# cslr_mcbsp_001 register map
Vendor: Texas Instruments
Peripheral module from a debugger description file.
Registers are 32-bit, access not given, reset 0x0 unless marked. A register's access mark holds for its fields unless they carry their own. Offsets are as the file gives them; lines under a group give offsets from that group; [hi:lo] are bit positions; {n}, {i} and the like mark numbered series; 'fields as' and 'values as' point back to an identical list; <NAME> marks a mode.

## MCBSP — McBSP512
0x00 DRR ro — Data Receive Register
  [31:0] DRR — Receive data
0x04 DXR rw — Data Transmit Register
  [31:0] DXR — Transmit data
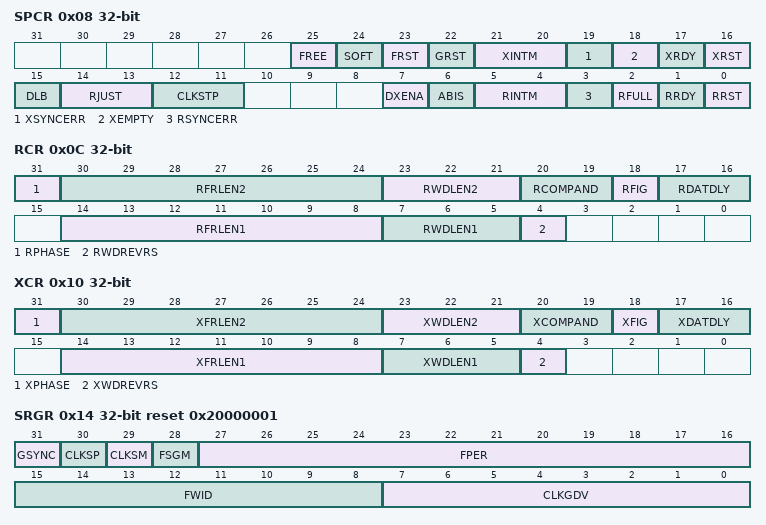
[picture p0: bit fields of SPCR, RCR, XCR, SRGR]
0x08 SPCR — Serial Port Control Register
  [25] FREE rw — McBSP emulation mode bit (free mode)
  [24] SOFT rw — McBSP emulation mode bit (soft mode)
  [23] FRST rw — Frame-sync logic reset bit (negative polarity)
  [22] GRST rw — Sample rate generator reset bit (negative polarity)
  [21:20] XINTM rw — Transmit interrupt mode bits
  [19] XSYNCERR rw — Transmit frame-sync error bit (Caution: if XINTM = 11b, writing a 1 to XSYNCERR triggers a transmit interrupt just as if a transmit frame-sync error occurred)
    0=CLEAR (Clear the transmit Frame Sync Error)
  [18] XEMPTY ro — Transmitter empty bit (negative polarity)
  [17] XRDY ro — Transmitter ready bit
  [16] XRST rw — Transmitter reset bit (negative polarity)
  [15] DLB rw — Digital loopback mode bit
  [14:13] RJUST rw — Receive sign-extension and justification mode bits
  [12:11] CLKSTP rw — Clock stop mode bits
  [7] DXENA rw — DX delay enabler mode bit
  [6] ABIS rw — A-bis mode bit
  [5:4] RINTM rw — Receive interrupt mode bits
  [3] RSYNCERR rw — Receive frame-sync error bit (Caution: If RINTM = 11b, writing a 1 to RSYNCERR triggers a receive interrupt just as if a receive frame-sync error occurred)
    0=CLEAR (Clear the receive Frame Sync Error)
  [2] RFULL ro — Receiver full bit
  [1] RRDY ro — Receiver ready bit
  [0] RRST rw — Receiver reset bit (negative polarity)
0x0C RCR — Receive Control Register
  [31] RPHASE rw — Receive phase number bit
  [30:24] RFRLEN2 rw — Receive frame length 2
  [23:21] RWDLEN2 rw — Receive word length 2
    0=8BITS; 1=12BITS; 2=16BITS; 3=20BITS; 4=24BITS; 5=32BITS
  [20:19] RCOMPAND rw — Receive companding mode bits
  [18] RFIG rw — Receive frame-sync ignore bit
  [17:16] RDATDLY rw — Receive data delay bits
  [14:8] RFRLEN1 rw — Receive frame length 1
  [7:5] RWDLEN1 rw — Receive word length 1
    0=8BITS; 1=12BITS; 2=16BITS; 3=20BITS; 4=24BITS; 5=32BITS
  [4] RWDREVRS rw — Receive 32-bit reversal feature 0: 32-bit reversal disabled 1: 32-bit reversal enabled. 32-bit data is received LSB first. RWDLEN should be set for 32-bit operation; else operation is undefined
0x10 XCR — Transmit Control Register
  [31] XPHASE rw — Transmit phase number bit
  [30:24] XFRLEN2 rw — Transmit frame length 2
  [23:21] XWDLEN2 rw — Transmit word length 2
    0=8BITS; 1=12BITS; 2=16BITS; 3=20BITS; 4=24BITS; 5=32BITS
  [20:19] XCOMPAND rw — Transmit companding mode bits
  [18] XFIG rw — Transmit frame-sync ignore bit
  [17:16] XDATDLY rw — Transmit data delay bits
  [14:8] XFRLEN1 rw — Transmit frame length 1
  [7:5] XWDLEN1 rw — Transmit word length 1
    0=8BITS; 1=12BITS; 2=16BITS; 3=20BITS; 4=24BITS; 5=32BITS
  [4] XWDREVRS rw — Transmit 32-bit reversal feature 0: 32-bit reversal disabled 1: 32-bit reversal enabled. 32-bit data is transmitted LSB first. RWDLEN should be set for 32-bit operation; else operation is undefined
0x14 SRGR rw reset 0x20000001 — Sample Rate Generator Register
  [31] GSYNC — Clock synchronization mode bit for CLKG
  [30] CLKSP — CLKS pin polarity bit
  [29] CLKSM — Sample rate generator input clock mode bit
  [28] FSGM — Sample rate generator transmit frame-sync mode bit
  [27:16] FPER — Frame-sync period bits for FSG
  [15:8] FWID — Frame-sync pulse width bits for FSG
  [7:0] CLKGDV — Divide-down value for CLKG
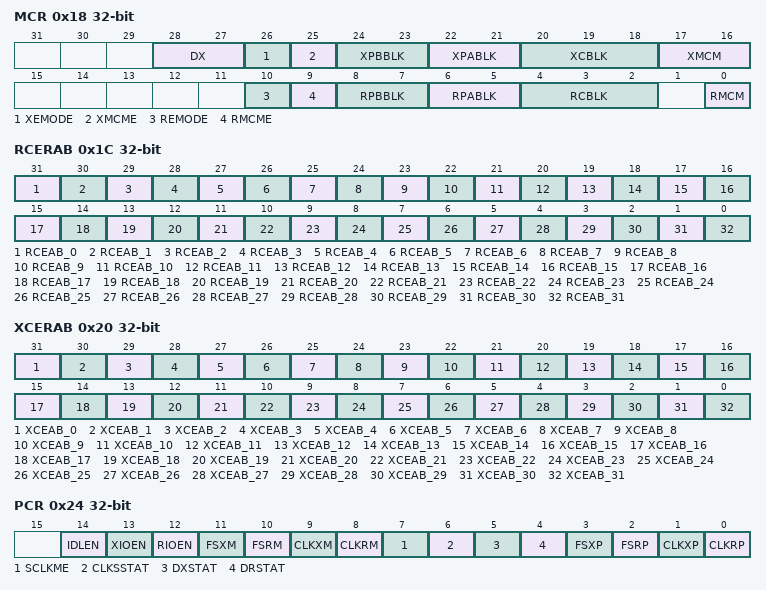
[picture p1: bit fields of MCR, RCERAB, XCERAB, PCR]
0x18 MCR — Multichannel Control Register
  [28:27] DX rw — Transmit pin mode configuration This is used to configure the DX pin state while the time slot is disabled 00b: Hi-Z 01b: Driven as 1 10b: Driven as 0 11b: Reserved
  [26] XEMODE rw — Multi-channel mode selection This bit is work with XMCM and XMCME bit to select the operation mode of the McBSP512 XEMODE XMCM XMCME Operation mode 0 00 0 Traditional operation mode 0 01/10/11 0 32 channel normal operation mode 0 xx 1 128 channel normal operation mode 1 00 0 512 channel mode with PDMA
  [25] XMCME rw — Transmit multichannel partition mode bit
    0=PARTITIONS2 (2-Partition Multi Channel Mode)
  [24:23] XPBBLK rw — Transmit partition B block bits
  [22:21] XPABLK rw — Transmit partition A block bits
  [20:18] XCBLK ro — Transmit current block indicator
  [17:16] XMCM rw — Transmit multichannel selection mode bits
    0=ENABLE (All Transmitter Channels are enabled); 1=DISABLE (All Transmitter Channels are disabled); 2=ENABLE_MASK (All Transmitter Channels are enabled and masked); 3=SYMMETRIC (Symmetric transmission and reception)
  [10] REMODE rw — Multi-channel mode selection This bit is work with RMCM and RMCME bit to select the operation mode of the McBSP512 REMODE RMCM RMCME Operation mode 0 00 0 Traditional operation mode 0 01/10/11 0 32 channel normal operation mode 0 xx 1 128 channel normal operation mode 1 00 0 512 channel mode with PDMA
  [9] RMCME rw — Receive multichannel partition mode bit
    0=PARTITIONS2 (2-Partition Multi Channel Mode); 1=PARTITIONS8 (8-Partition Multi Channel Mode)
  [8:7] RPBBLK rw — Receive partition B block bits
  [6:5] RPABLK rw — Receive partition A block bits
  [4:2] RCBLK ro — Receive current block indicator
  [0] RMCM rw — Receive multichannel selection mode bit
    0=ENABLE (All Receiver Channels are enabled); 1=DISABLE (All Receiver Channels are disabled)
0x1C RCERAB rw — Receive Channel Enable Register for Partition A and B
  [31-n] RCEAB_{n} (n=0..31) — Receive channel enable bits for partition A and B
0x20 XCERAB rw — Transmit Channel Enable Register for Partition A and B
  [31-n] XCEAB_{n} (n=0..31) — Transmit channel enable bits for partition A and B
0x24 PCR — Pin Control Register
  [14] IDLEN rw — Idle enable bit for the McBSP
  [13] XIOEN rw — Transmit I/O enable bit
  [12] RIOEN rw — Receive I/O enable bit
  [11] FSXM rw — Transmit frame-sync mode bit
    0=INPUT (Select FSX as Input Pin); 1=OUTPUT (Select FSX as Output Pin)
  [10] FSRM rw — Receive frame-sync mode bit
    0=INPUT (Select FSR as Input Pin); 1=OUTPUT (Select FSR as Output Pin)
  [9] CLKXM rw — Transmit clock mode bit
    0=INPUT (Select CLKX as Input Pin); 1=OUTPUT (Select CLKX as Output Pin)
  [8] CLKRM rw — Receive clock mode bit
    0=INPUT (Select CLKR as Input Pin); 1=OUTPUT (Select CLKR as Output Pin)
  [7] SCLKME rw — Sample rate generator input clock mode bit
  [6] CLKSSTAT ro — CLKS pin status bit
  [5] DXSTAT rw — DX pin status bit
  [4] DRSTAT ro — DR pin status bit
  [3] FSXP rw — Transmit frame-sync polarity bit
  [2] FSRP rw — Receive frame-sync polarity bit
  [1] CLKXP rw — Transmit clock polarity bit
  [0] CLKRP rw — Receive clock polarity bit
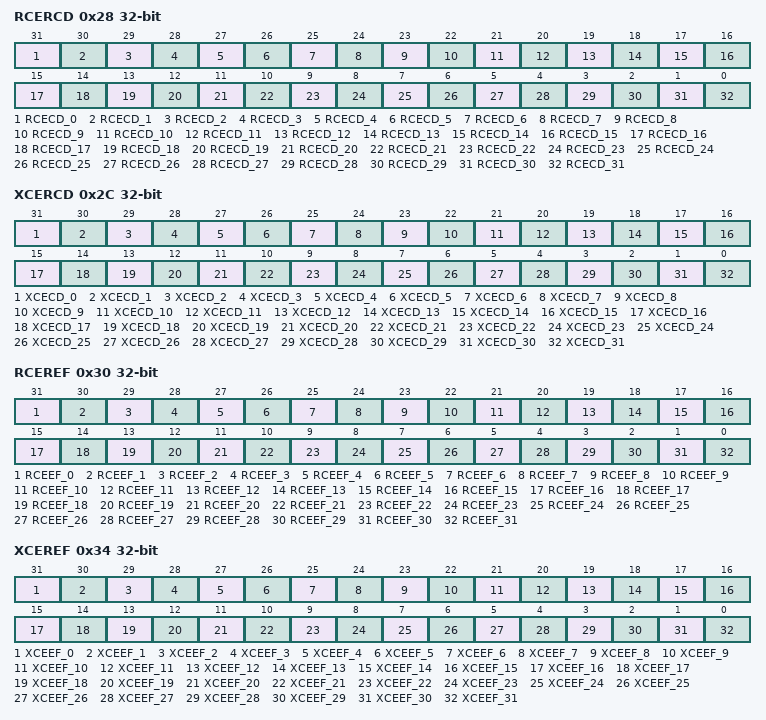
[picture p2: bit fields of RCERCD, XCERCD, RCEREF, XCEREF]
0x28 RCERCD rw — Receive Channel Enable Register for Partition C and D
  [31-n] RCECD_{n} (n=0..31) — Receive channel enable bits for partition C and D
0x2C XCERCD rw — Transmit Channel Enable Register for Partition C and D
  [31-n] XCECD_{n} (n=0..31) — Transmit channel enable bits for partition C and D
0x30 RCEREF rw — Receive Channel Enable Register for Partition E and F
  [31-n] RCEEF_{n} (n=0..31) — Receive channel enable bits for partition E and F
0x34 XCEREF rw — Transmit Channel Enable Register for Partition E and F
  [31-n] XCEEF_{n} (n=0..31) — Transmit channel enable bits for partition E and F
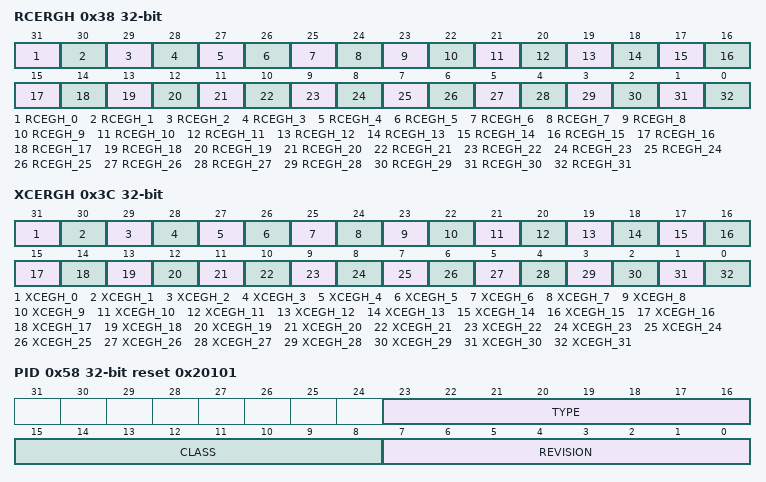
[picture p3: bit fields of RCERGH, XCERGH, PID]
0x38 RCERGH rw — Receive Channel Enable Register for Partition G and H
  [31-n] RCEGH_{n} (n=0..31) — Receive channel enable bits for partition G and H
0x3C XCERGH rw — Transmit Channel Enable Register for Partition G and H
  [31-n] XCEGH_{n} (n=0..31) — Transmit channel enable bits for partition G and H
0x40 REVTCR — Receive Synchronization Event Channel Identification Register
  [8:0] REVTCI ro — The time slot (channel number) which send out the synchronization event
0x44 XEVTCR — Transmit Synchronization Event Channel Identification Register
  [8:0] XEVTCI ro — The time slot (channel number) which send out the synchronization event
0x48 RFLR — Receive Frame Length Register
  [8:0] RFRLEN3 rw — Used to extend the receive frame length to 512 channels (words / frame)
0x4C XFLR — Transmit Frame Length Register
  [8:0] XFRLEN3 rw — Used to extend the receive frame length to 512 channels (words / frame)
0x50 RSYNCCNT — Receive Frame Synchronization Counter Register
  [15:0] RCOUNT rw — The number of frame synchronization pulse that must be received before the EN_SYNC pulse is created (for the super-frame synchronization)
0x54 XSYNCCNT — Transmit Frame Synchronization Counter Register
  [15:0] XCOUNT rw — The number of frame synchronization pulse that must be received before the EN_SYNC pulse is created (for the super-frame synchronization)
0x58 PID reset 0x20101 — Peripheral ID Register
  [23:16] TYPE ro — Identifies the Type of peripheral
  [15:8] CLASS ro — Identifies the class of the McBSP512 peripheral
  [7:0] REVISION ro — Identifies the revision level of the McBSP512
